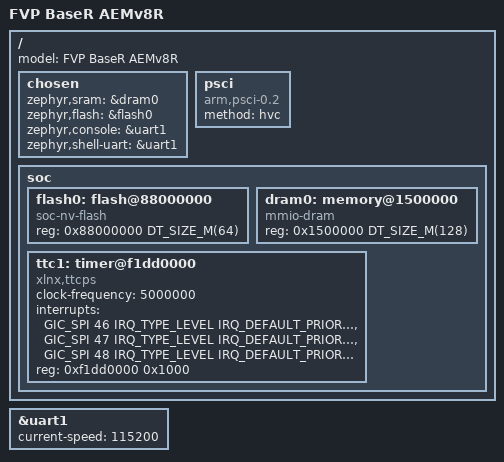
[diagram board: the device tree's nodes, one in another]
/*
 * Copyright (c) 2021 Arm Limited (or its affiliates). All rights reserved.
 * SPDX-License-Identifier: Apache-2.0
 */

/dts-v1/;

#include <arm64/fvp/fvp-aemv8r.dtsi>

/ {
	model = "FVP BaseR AEMv8R";

	chosen {
		/*
		 * The SRAM node is actually located in the
		 * DRAM region of the FVP BaseR AEMv8R.
		 */
		zephyr,sram = &dram0;
		zephyr,flash = &flash0;
		zephyr,console = &uart1;
		zephyr,shell-uart = &uart1;
	};

	psci {
		compatible = "arm,psci-0.2";
		method = "hvc";
	};

	soc {
		flash0: flash@88000000 {
			compatible = "soc-nv-flash";
			reg = <0x88000000 DT_SIZE_M(64)>;
		};

		dram0: memory@1500000 {
			compatible = "mmio-dram";
			reg = <0x1500000 DT_SIZE_M(128)>;
		};

        ttc1: timer@f1dd0000 {
            compatible = "xlnx,ttcps";
            clock-frequency = <5000000>;
            status = "okay";
            interrupts = <GIC_SPI 46 IRQ_TYPE_LEVEL
                    IRQ_DEFAULT_PRIORITY>,
                     <GIC_SPI 47 IRQ_TYPE_LEVEL
                    IRQ_DEFAULT_PRIORITY>,
                     <GIC_SPI 48 IRQ_TYPE_LEVEL
                    IRQ_DEFAULT_PRIORITY>;
            interrupt-names = "irq_0", "irq_1", "irq_2";
            reg = <0xf1dd0000 0x1000>;
        };
	};
};

&uart1 {
	status = "okay";
	current-speed = <115200>;
};
